# Espressif register map
File version: 1.0
CPU: Xtensa LX6 1, little endian, no MPU, FPU, 3 interrupt priority bits
Registers are 32-bit, access not given, reset 0x0 unless marked. A register's access mark holds for its fields unless they carry their own. Offsets are from the block's base; [hi:lo] are bit positions; {n}, {i} and the like mark numbered series.

## LEDC
Base 0x3FF59000
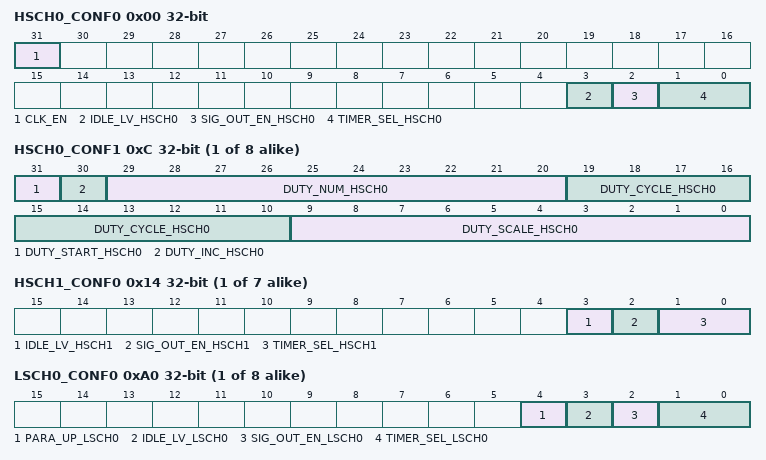
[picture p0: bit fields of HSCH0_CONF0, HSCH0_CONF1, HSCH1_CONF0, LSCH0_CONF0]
0x00 HSCH0_CONF0 — LEDC_HSCH0_CONF0
  [31] CLK_EN, [3] IDLE_LV_HSCH0, [2] SIG_OUT_EN_HSCH0, [1:0] TIMER_SEL_HSCH0
{0x4+0x14*i} HSCH{i}_HPOINT (i=0..7) — LEDC_HSCH{i}_HPOINT
  [19:0] HPOINT_HSCH{i}
{0x8+0x14*i} HSCH{i}_DUTY (i=0..7) — LEDC_HSCH{i}_DUTY
  [24:0] DUTY_HSCH{i}
{0xC+0x14*i} HSCH{i}_CONF1 (i=0..7) — LEDC_HSCH{i}_CONF1
  [31] DUTY_START_HSCH{i}, [30] DUTY_INC_HSCH{i}, [29:20] DUTY_NUM_HSCH{i}, [19:10] DUTY_CYCLE_HSCH{i}, [9:0] DUTY_SCALE_HSCH{i}
{0x10+0x14*i} HSCH{i}_DUTY_R (i=0..7) — LEDC_HSCH{i}_DUTY_R
  [24:0] DUTY_HSCH{i}
{0x0+0x14*i} HSCH{i}_CONF0 (i=1..7) — LEDC_HSCH{i}_CONF0
  [3] IDLE_LV_HSCH{i}, [2] SIG_OUT_EN_HSCH{i}, [1:0] TIMER_SEL_HSCH{i}
{0xA0+0x14*i} LSCH{i}_CONF0 (i=0..7) — LEDC_LSCH{i}_CONF0
  [4] PARA_UP_LSCH{i}, [3] IDLE_LV_LSCH{i}, [2] SIG_OUT_EN_LSCH{i}, [1:0] TIMER_SEL_LSCH{i}
{0xA4+0x14*i} LSCH{i}_HPOINT (i=0..7) — LEDC_LSCH{i}_HPOINT
  [19:0] HPOINT_LSCH{i}
{0xA8+0x14*i} LSCH{i}_DUTY (i=0..7) — LEDC_LSCH{i}_DUTY
  [24:0] DUTY_LSCH{i}
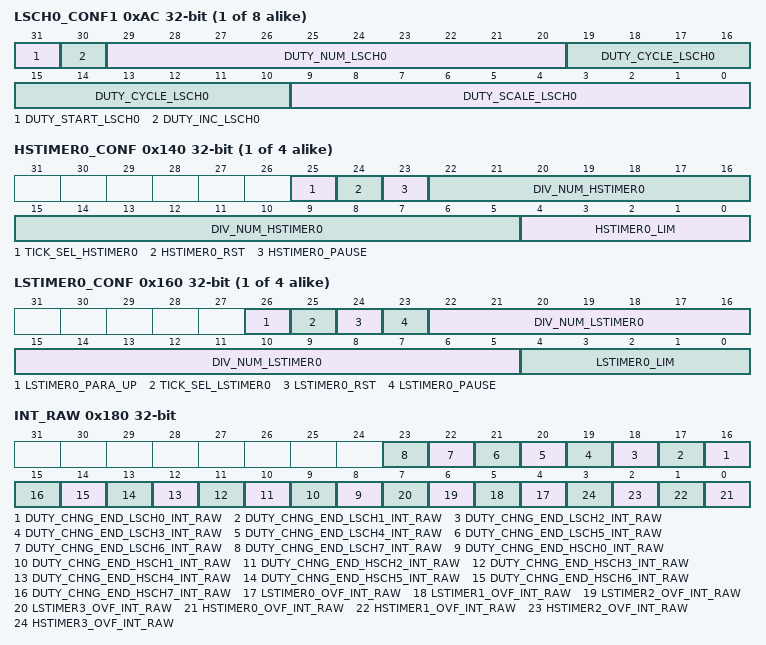
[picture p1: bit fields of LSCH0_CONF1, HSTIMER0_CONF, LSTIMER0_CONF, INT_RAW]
{0xAC+0x14*i} LSCH{i}_CONF1 (i=0..7) — LEDC_LSCH{i}_CONF1
  [31] DUTY_START_LSCH{i}, [30] DUTY_INC_LSCH{i}, [29:20] DUTY_NUM_LSCH{i}, [19:10] DUTY_CYCLE_LSCH{i}, [9:0] DUTY_SCALE_LSCH{i}
{0xB0+0x14*i} LSCH{i}_DUTY_R (i=0..7) — LEDC_LSCH{i}_DUTY_R
  [24:0] DUTY_LSCH{i}
{0x140+8i} HSTIMER{i}_CONF (i=0..3) — LEDC_HSTIMER{i}_CONF
  [25] TICK_SEL_HSTIMER{i}, [24] HSTIMER{i}_RST, [23] HSTIMER{i}_PAUSE, [22:5] DIV_NUM_HSTIMER{i}, [4:0] HSTIMER{i}_LIM
{0x144+8i} HSTIMER{i}_VALUE (i=0..3) — LEDC_HSTIMER{i}_VALUE
  [19:0] HSTIMER{i}_CNT
{0x160+8i} LSTIMER{i}_CONF (i=0..3) — LEDC_LSTIMER{i}_CONF
  [26] LSTIMER{i}_PARA_UP, [25] TICK_SEL_LSTIMER{i}, [24] LSTIMER{i}_RST, [23] LSTIMER{i}_PAUSE, [22:5] DIV_NUM_LSTIMER{i}, [4:0] LSTIMER{i}_LIM
{0x164+8i} LSTIMER{i}_VALUE (i=0..3) — LEDC_LSTIMER{i}_VALUE
  [19:0] LSTIMER{i}_CNT
0x180 INT_RAW — LEDC_INT_RAW
  [n+16] DUTY_CHNG_END_LSCH{n}_INT_RAW (n=0..7), [n+8] DUTY_CHNG_END_HSCH{n}_INT_RAW (n=0..7), [n+4] LSTIMER{n}_OVF_INT_RAW (n=0..3), [n] HSTIMER{n}_OVF_INT_RAW (n=0..3)
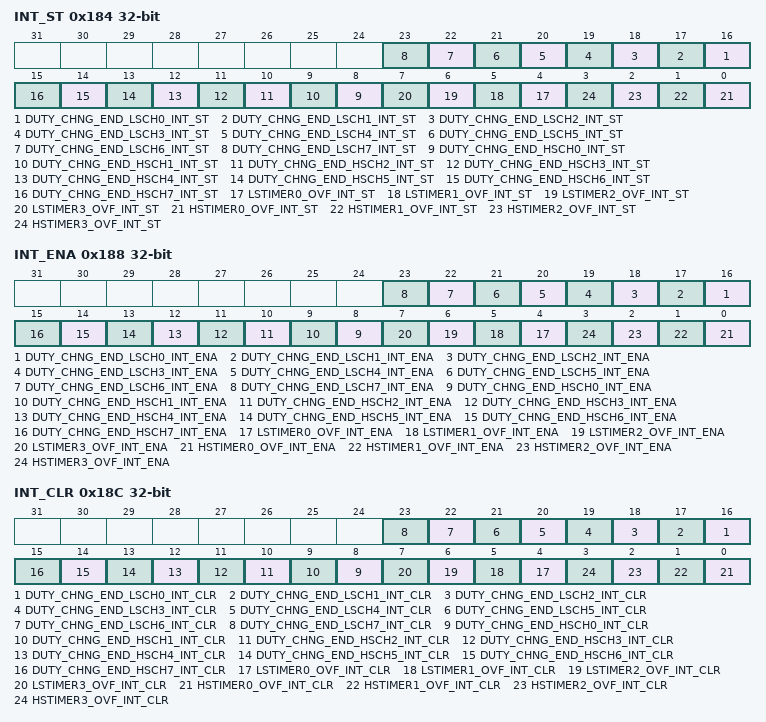
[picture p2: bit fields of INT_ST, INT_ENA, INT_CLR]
0x184 INT_ST — LEDC_INT_ST
  [n+16] DUTY_CHNG_END_LSCH{n}_INT_ST (n=0..7), [n+8] DUTY_CHNG_END_HSCH{n}_INT_ST (n=0..7), [n+4] LSTIMER{n}_OVF_INT_ST (n=0..3), [n] HSTIMER{n}_OVF_INT_ST (n=0..3)
0x188 INT_ENA — LEDC_INT_ENA
  [n+16] DUTY_CHNG_END_LSCH{n}_INT_ENA (n=0..7), [n+8] DUTY_CHNG_END_HSCH{n}_INT_ENA (n=0..7), [n+4] LSTIMER{n}_OVF_INT_ENA (n=0..3), [n] HSTIMER{n}_OVF_INT_ENA (n=0..3)
0x18C INT_CLR — LEDC_INT_CLR
  [n+16] DUTY_CHNG_END_LSCH{n}_INT_CLR (n=0..7), [n+8] DUTY_CHNG_END_HSCH{n}_INT_CLR (n=0..7), [n+4] LSTIMER{n}_OVF_INT_CLR (n=0..3), [n] HSTIMER{n}_OVF_INT_CLR (n=0..3)
0x190 CONF — LEDC_CONF
  [0] APB_CLK_SEL
0x1FC DATE — LEDC_DATE

## TIMG0
Base 0x3FF5F000
Same registers: TIMG1 0x3FF60000
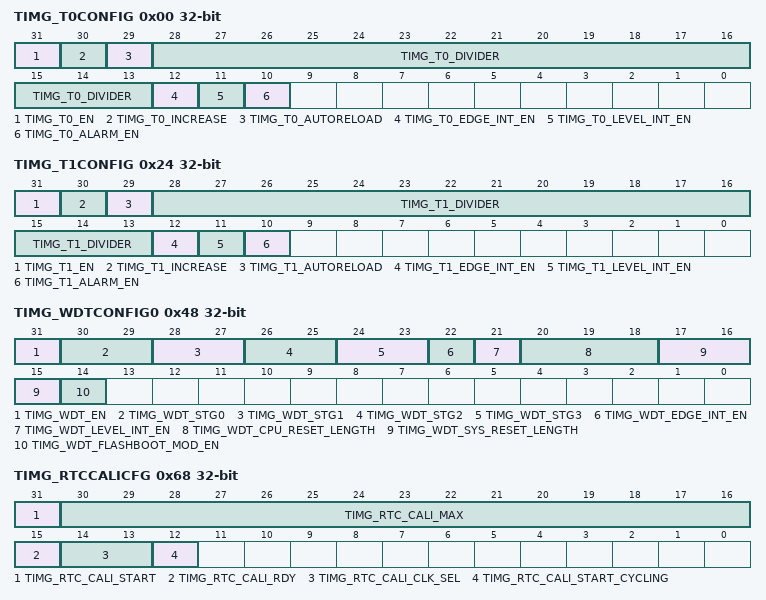
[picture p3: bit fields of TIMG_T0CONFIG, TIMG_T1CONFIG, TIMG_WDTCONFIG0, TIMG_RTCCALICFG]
0x00 TIMG_T0CONFIG
  [31] TIMG_T0_EN, [30] TIMG_T0_INCREASE, [29] TIMG_T0_AUTORELOAD, [28:13] TIMG_T0_DIVIDER, [12] TIMG_T0_EDGE_INT_EN, [11] TIMG_T0_LEVEL_INT_EN, [10] TIMG_T0_ALARM_EN
0x04 TIMG_T0LO
  [31:0] TIMG_T0_LO
0x08 TIMG_T0HI
  [31:0] TIMG_T0_HI
0x0C TIMG_T0UPDATE
  [31:0] TIMG_T0_UPDATE
0x10 TIMG_T0ALARMLO
  [31:0] TIMG_T0_ALARM_LO
0x14 TIMG_T0ALARMHI
  [31:0] TIMG_T0_ALARM_HI
0x18 TIMG_T0LOADLO
  [31:0] TIMG_T0_LOAD_LO
0x1C TIMG_T0LOADHI
  [31:0] TIMG_T0_LOAD_HI
0x20 TIMG_T0LOAD
  [31:0] TIMG_T0_LOAD
0x24 TIMG_T1CONFIG
  [31] TIMG_T1_EN, [30] TIMG_T1_INCREASE, [29] TIMG_T1_AUTORELOAD, [28:13] TIMG_T1_DIVIDER, [12] TIMG_T1_EDGE_INT_EN, [11] TIMG_T1_LEVEL_INT_EN, [10] TIMG_T1_ALARM_EN
0x28 TIMG_T1LO
  [31:0] TIMG_T1_LO
0x2C TIMG_T1HI
  [31:0] TIMG_T1_HI
0x30 TIMG_T1UPDATE
  [31:0] TIMG_T1_UPDATE
0x34 TIMG_T1ALARMLO
  [31:0] TIMG_T1_ALARM_LO
0x38 TIMG_T1ALARMHI
  [31:0] TIMG_T1_ALARM_HI
0x3C TIMG_T1LOADLO
  [31:0] TIMG_T1_LOAD_LO
0x40 TIMG_T1LOADHI
  [31:0] TIMG_T1_LOAD_HI
0x44 TIMG_T1LOAD
  [31:0] TIMG_T1_LOAD
0x48 TIMG_WDTCONFIG0
  [31] TIMG_WDT_EN, [30-2n:29-2n] TIMG_WDT_STG{n} (n=0..3), [22] TIMG_WDT_EDGE_INT_EN, [21] TIMG_WDT_LEVEL_INT_EN, [20:18] TIMG_WDT_CPU_RESET_LENGTH, [17:15] TIMG_WDT_SYS_RESET_LENGTH, [14] TIMG_WDT_FLASHBOOT_MOD_EN
0x4C TIMG_WDTCONFIG1
  [31:16] TIMG_WDT_CLK_PRESCALE
{0x48+4i} TIMG_WDTCONFIG{i} (i=2..5)
  [31:0] TIMG_WDT_STG{i-2}_HOLD
0x60 TIMG_WDTFEED
  [31:0] TIMG_WDT_FEED
0x64 TIMG_WDTWPROTECT
  [31:0] TIMG_WDT_WKEY
0x68 TIMG_RTCCALICFG
  [31] TIMG_RTC_CALI_START, [30:16] TIMG_RTC_CALI_MAX, [15] TIMG_RTC_CALI_RDY, [14:13] TIMG_RTC_CALI_CLK_SEL, [12] TIMG_RTC_CALI_START_CYCLING
0x6C TIMG_RTCCALICFG1
  [31:7] TIMG_RTC_CALI_VALUE
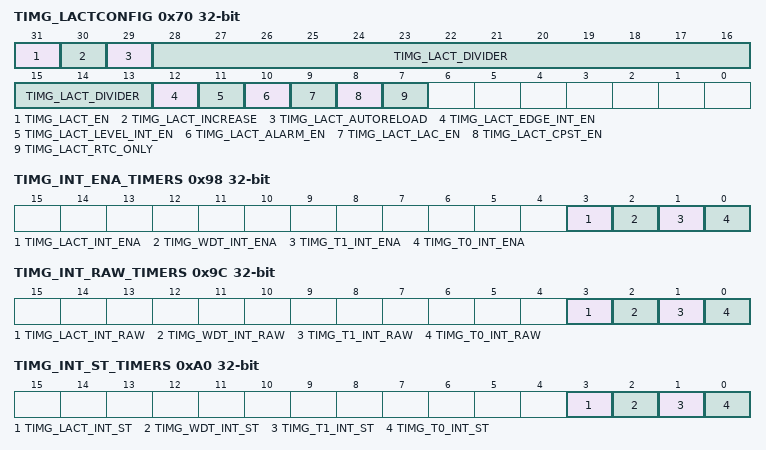
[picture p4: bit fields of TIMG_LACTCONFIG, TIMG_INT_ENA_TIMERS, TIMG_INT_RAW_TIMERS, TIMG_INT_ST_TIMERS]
0x70 TIMG_LACTCONFIG
  [31] TIMG_LACT_EN, [30] TIMG_LACT_INCREASE, [29] TIMG_LACT_AUTORELOAD, [28:13] TIMG_LACT_DIVIDER, [12] TIMG_LACT_EDGE_INT_EN, [11] TIMG_LACT_LEVEL_INT_EN, [10] TIMG_LACT_ALARM_EN, [9] TIMG_LACT_LAC_EN, [8] TIMG_LACT_CPST_EN, [7] TIMG_LACT_RTC_ONLY
0x74 TIMG_LACTRTC
  [31:6] TIMG_LACT_RTC_STEP_LEN
0x78 TIMG_LACTLO
  [31:0] TIMG_LACT_LO
0x7C TIMG_LACTHI
  [31:0] TIMG_LACT_HI
0x80 TIMG_LACTUPDATE
  [31:0] TIMG_LACT_UPDATE
0x84 TIMG_LACTALARMLO
  [31:0] TIMG_LACT_ALARM_LO
0x88 TIMG_LACTALARMHI
  [31:0] TIMG_LACT_ALARM_HI
0x8C TIMG_LACTLOADLO
  [31:0] TIMG_LACT_LOAD_LO
0x90 TIMG_LACTLOADHI
  [31:0] TIMG_LACT_LOAD_HI
0x94 TIMG_LACTLOAD
  [31:0] TIMG_LACT_LOAD
0x98 TIMG_INT_ENA_TIMERS
  [3] TIMG_LACT_INT_ENA, [2] TIMG_WDT_INT_ENA, [1] TIMG_T1_INT_ENA, [0] TIMG_T0_INT_ENA
0x9C TIMG_INT_RAW_TIMERS
  [3] TIMG_LACT_INT_RAW, [2] TIMG_WDT_INT_RAW, [1] TIMG_T1_INT_RAW, [0] TIMG_T0_INT_RAW
0xA0 TIMG_INT_ST_TIMERS
  [3] TIMG_LACT_INT_ST, [2] TIMG_WDT_INT_ST, [1] TIMG_T1_INT_ST, [0] TIMG_T0_INT_ST
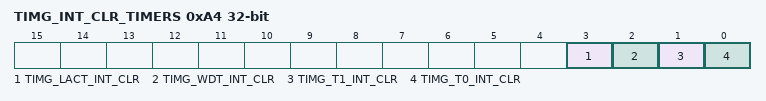
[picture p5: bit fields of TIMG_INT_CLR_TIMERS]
0xA4 TIMG_INT_CLR_TIMERS
  [3] TIMG_LACT_INT_CLR, [2] TIMG_WDT_INT_CLR, [1] TIMG_T1_INT_CLR, [0] TIMG_T0_INT_CLR
0xF8 TIMG_NTIMERS_DATE
  [27:0] TIMG_NTIMERS_DATE
0xFC TIMGCLK
  [31] TIMG_CLK_EN

## I2C0
Base 0x00000000
Same registers: I2C1 0x00000000
0x00 I2C_SCL_LOW_PERIOD
  [13:0] I2C_SCL_LOW_PERIOD
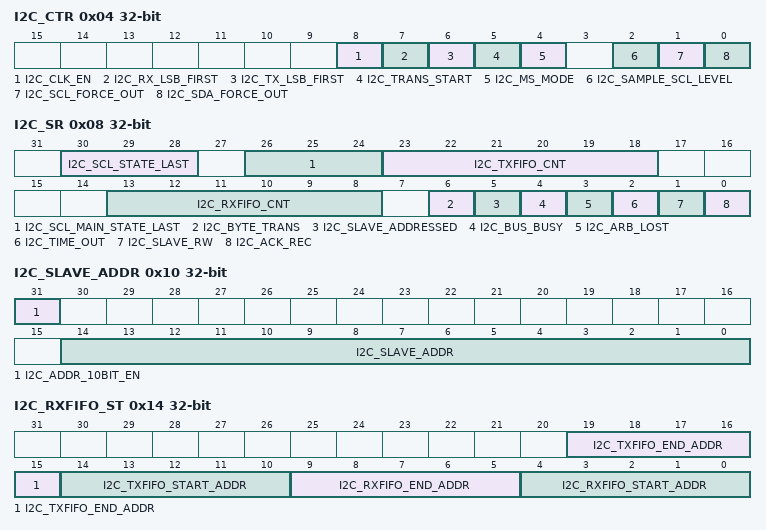
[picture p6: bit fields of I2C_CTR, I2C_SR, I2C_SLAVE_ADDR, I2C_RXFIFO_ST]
0x04 I2C_CTR
  [8] I2C_CLK_EN, [7] I2C_RX_LSB_FIRST, [6] I2C_TX_LSB_FIRST, [5] I2C_TRANS_START, [4] I2C_MS_MODE, [2] I2C_SAMPLE_SCL_LEVEL, [1] I2C_SCL_FORCE_OUT, [0] I2C_SDA_FORCE_OUT
0x08 I2C_SR
  [30:28] I2C_SCL_STATE_LAST, [26:24] I2C_SCL_MAIN_STATE_LAST, [23:18] I2C_TXFIFO_CNT, [13:8] I2C_RXFIFO_CNT, [6] I2C_BYTE_TRANS, [5] I2C_SLAVE_ADDRESSED, [4] I2C_BUS_BUSY, [3] I2C_ARB_LOST, [2] I2C_TIME_OUT, [1] I2C_SLAVE_RW, [0] I2C_ACK_REC
0x0C I2C_TO
  [19:0] I2C_TIME_OUT_REG
0x10 I2C_SLAVE_ADDR
  [31] I2C_ADDR_10BIT_EN, [14:0] I2C_SLAVE_ADDR
0x14 I2C_RXFIFO_ST
  [19:15] I2C_TXFIFO_END_ADDR, [14:10] I2C_TXFIFO_START_ADDR, [9:5] I2C_RXFIFO_END_ADDR, [4:0] I2C_RXFIFO_START_ADDR
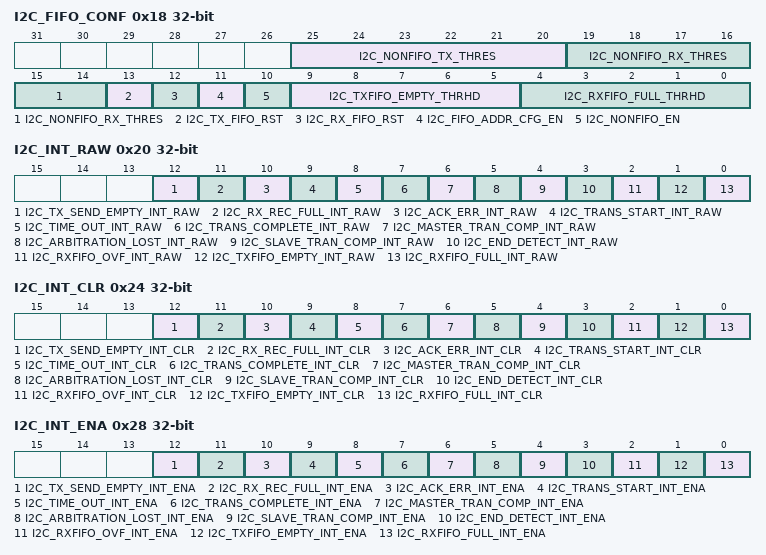
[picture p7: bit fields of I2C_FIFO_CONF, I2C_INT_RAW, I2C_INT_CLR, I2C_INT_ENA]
0x18 I2C_FIFO_CONF
  [25:20] I2C_NONFIFO_TX_THRES, [19:14] I2C_NONFIFO_RX_THRES, [13] I2C_TX_FIFO_RST, [12] I2C_RX_FIFO_RST, [11] I2C_FIFO_ADDR_CFG_EN, [10] I2C_NONFIFO_EN, [9:5] I2C_TXFIFO_EMPTY_THRHD, [4:0] I2C_RXFIFO_FULL_THRHD
0x1C I2C_DATA
  [7:0] I2C_FIFO_RDATA
0x20 I2C_INT_RAW
  [12] I2C_TX_SEND_EMPTY_INT_RAW, [11] I2C_RX_REC_FULL_INT_RAW, [10] I2C_ACK_ERR_INT_RAW, [9] I2C_TRANS_START_INT_RAW, [8] I2C_TIME_OUT_INT_RAW, [7] I2C_TRANS_COMPLETE_INT_RAW, [6] I2C_MASTER_TRAN_COMP_INT_RAW, [5] I2C_ARBITRATION_LOST_INT_RAW, [4] I2C_SLAVE_TRAN_COMP_INT_RAW, [3] I2C_END_DETECT_INT_RAW, [2] I2C_RXFIFO_OVF_INT_RAW, [1] I2C_TXFIFO_EMPTY_INT_RAW, [0] I2C_RXFIFO_FULL_INT_RAW
0x24 I2C_INT_CLR
  [12] I2C_TX_SEND_EMPTY_INT_CLR, [11] I2C_RX_REC_FULL_INT_CLR, [10] I2C_ACK_ERR_INT_CLR, [9] I2C_TRANS_START_INT_CLR, [8] I2C_TIME_OUT_INT_CLR, [7] I2C_TRANS_COMPLETE_INT_CLR, [6] I2C_MASTER_TRAN_COMP_INT_CLR, [5] I2C_ARBITRATION_LOST_INT_CLR, [4] I2C_SLAVE_TRAN_COMP_INT_CLR, [3] I2C_END_DETECT_INT_CLR, [2] I2C_RXFIFO_OVF_INT_CLR, [1] I2C_TXFIFO_EMPTY_INT_CLR, [0] I2C_RXFIFO_FULL_INT_CLR
0x28 I2C_INT_ENA
  [12] I2C_TX_SEND_EMPTY_INT_ENA, [11] I2C_RX_REC_FULL_INT_ENA, [10] I2C_ACK_ERR_INT_ENA, [9] I2C_TRANS_START_INT_ENA, [8] I2C_TIME_OUT_INT_ENA, [7] I2C_TRANS_COMPLETE_INT_ENA, [6] I2C_MASTER_TRAN_COMP_INT_ENA, [5] I2C_ARBITRATION_LOST_INT_ENA, [4] I2C_SLAVE_TRAN_COMP_INT_ENA, [3] I2C_END_DETECT_INT_ENA, [2] I2C_RXFIFO_OVF_INT_ENA, [1] I2C_TXFIFO_EMPTY_INT_ENA, [0] I2C_RXFIFO_FULL_INT_ENA
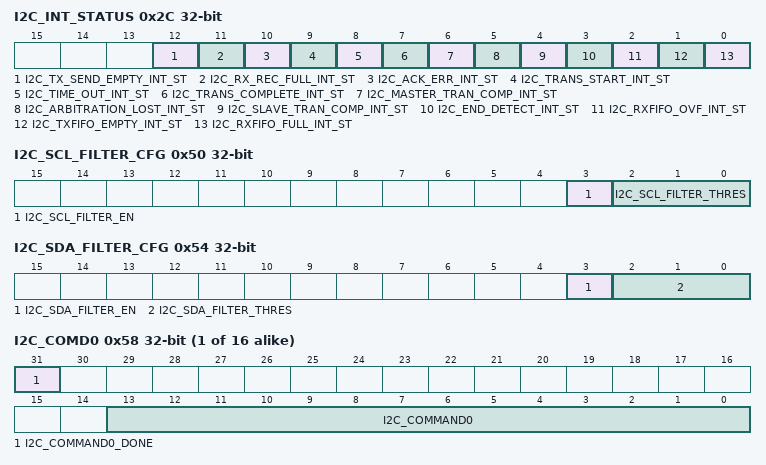
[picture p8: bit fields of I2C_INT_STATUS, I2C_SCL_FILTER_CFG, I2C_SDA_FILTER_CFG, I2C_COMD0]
0x2C I2C_INT_STATUS
  [12] I2C_TX_SEND_EMPTY_INT_ST, [11] I2C_RX_REC_FULL_INT_ST, [10] I2C_ACK_ERR_INT_ST, [9] I2C_TRANS_START_INT_ST, [8] I2C_TIME_OUT_INT_ST, [7] I2C_TRANS_COMPLETE_INT_ST, [6] I2C_MASTER_TRAN_COMP_INT_ST, [5] I2C_ARBITRATION_LOST_INT_ST, [4] I2C_SLAVE_TRAN_COMP_INT_ST, [3] I2C_END_DETECT_INT_ST, [2] I2C_RXFIFO_OVF_INT_ST, [1] I2C_TXFIFO_EMPTY_INT_ST, [0] I2C_RXFIFO_FULL_INT_ST
0x30 I2C_SDA_HOLD
  [9:0] I2C_SDA_HOLD_TIME
0x34 I2C_SDA_SAMPLE
  [9:0] I2C_SDA_SAMPLE_TIME
0x38 I2C_SCL_HIGH_PERIOD
  [13:0] I2C_SCL_HIGH_PERIOD
0x40 I2C_SCL_START_HOLD
  [9:0] I2C_SCL_START_HOLD_TIME
0x44 I2C_SCL_RSTART_SETUP
  [9:0] I2C_SCL_RSTART_SETUP_TIME
0x48 I2C_SCL_STOP_HOLD
  [13:0] I2C_SCL_STOP_HOLD_TIME
0x4C I2C_SCL_STOP_SETUP
  [9:0] I2C_SCL_STOP_SETUP_TIME
0x50 I2C_SCL_FILTER_CFG
  [3] I2C_SCL_FILTER_EN, [2:0] I2C_SCL_FILTER_THRES
0x54 I2C_SDA_FILTER_CFG
  [3] I2C_SDA_FILTER_EN, [2:0] I2C_SDA_FILTER_THRES
{0x58+4i} I2C_COMD{i} (i=0..15)
  [31] I2C_COMMAND{i}_DONE, [13:0] I2C_COMMAND{i}
0xF8 I2C_DATE
